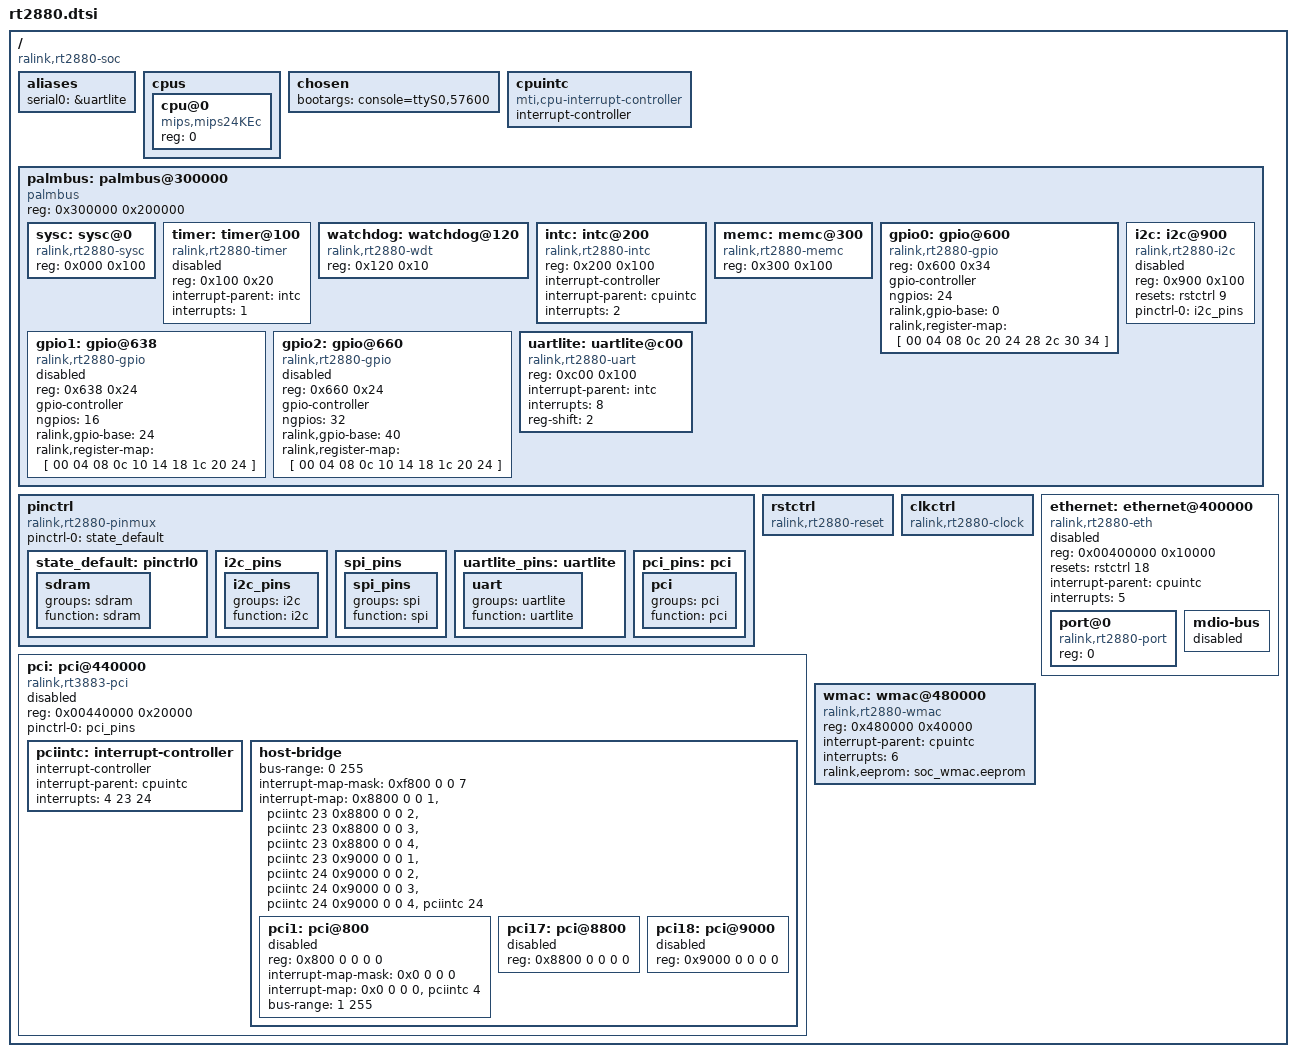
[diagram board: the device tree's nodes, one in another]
/dts-v1/;

/ {
	#address-cells = <1>;
	#size-cells = <1>;
	compatible = "ralink,rt2880-soc";

	aliases {
		serial0 = &uartlite;
	};

	cpus {
		#address-cells = <1>;
		#size-cells = <0>;

		cpu@0 {
			compatible = "mips,mips24KEc";
			reg = <0>;
		};
	};

	chosen {
		bootargs = "console=ttyS0,57600";
	};

	cpuintc: cpuintc {
		#address-cells = <0>;
		#interrupt-cells = <1>;
		interrupt-controller;
		compatible = "mti,cpu-interrupt-controller";
	};

	palmbus: palmbus@300000 {
		compatible = "palmbus";
		reg = <0x300000 0x200000>;
		ranges = <0x0 0x300000 0x1FFFFF>;

		#address-cells = <1>;
		#size-cells = <1>;

		sysc: sysc@0 {
			compatible = "ralink,rt2880-sysc";
			reg = <0x000 0x100>;
		};

		timer: timer@100 {
			compatible = "ralink,rt2880-timer";
			reg = <0x100 0x20>;

			interrupt-parent = <&intc>;
			interrupts = <1>;

			status = "disabled";
		};

		watchdog: watchdog@120 {
			compatible = "ralink,rt2880-wdt";
			reg = <0x120 0x10>;
		};

		intc: intc@200 {
			compatible = "ralink,rt2880-intc";
			reg = <0x200 0x100>;

			interrupt-controller;
			#interrupt-cells = <1>;

			interrupt-parent = <&cpuintc>;
			interrupts = <2>;
		};

		memc: memc@300 {
			compatible = "ralink,rt2880-memc";
			reg = <0x300 0x100>;
		};

		gpio0: gpio@600 {
			compatible = "ralink,rt2880-gpio";
			reg = <0x600 0x34>;

			gpio-controller;
			#gpio-cells = <2>;

			ngpios = <24>;
			ralink,gpio-base = <0>;
			ralink,register-map = [ 00 04 08 0c
						20 24 28 2c
						30 34 ];
		};

		gpio1: gpio@638 {
			compatible = "ralink,rt2880-gpio";
			reg = <0x638 0x24>;

			gpio-controller;
			#gpio-cells = <2>;

			ngpios = <16>;
			ralink,gpio-base = <24>;
			ralink,register-map = [ 00 04 08 0c
						10 14 18 1c
						20 24 ];

			status = "disabled";
		};

		gpio2: gpio@660 {
			compatible = "ralink,rt2880-gpio";
			reg = <0x660 0x24>;

			gpio-controller;
			#gpio-cells = <2>;

			ngpios = <32>;
			ralink,gpio-base = <40>;
			ralink,register-map = [ 00 04 08 0c
						10 14 18 1c
						20 24 ];

			status = "disabled";
		};

		i2c: i2c@900 {
			compatible = "ralink,rt2880-i2c";
			reg = <0x900 0x100>;

			resets = <&rstctrl 9>;
			reset-names = "i2c";

			#address-cells = <1>;
			#size-cells = <0>;

			status = "disabled";

			pinctrl-names = "default";
			pinctrl-0 = <&i2c_pins>;
		};

		uartlite: uartlite@c00 {
			compatible = "ralink,rt2880-uart", "ns16550a";
			reg = <0xc00 0x100>;

			interrupt-parent = <&intc>;
			interrupts = <8>;

			reg-shift = <2>;
		};
	};

	pinctrl: pinctrl {
		compatible = "ralink,rt2880-pinmux";

		pinctrl-names = "default";
		pinctrl-0 = <&state_default>;

		state_default: pinctrl0 {
			sdram {
				groups = "sdram";
				function = "sdram";
			};
		};

		i2c_pins: i2c_pins {
			i2c_pins {
				groups = "i2c";
				function = "i2c";
			};
		};

		spi_pins: spi_pins {
			spi_pins {
				groups = "spi";
				function = "spi";
			};
		};

		uartlite_pins: uartlite {
			uart {
				groups = "uartlite";
				function = "uartlite";
			};
		};

		pci_pins: pci {
			pci {
				groups = "pci";
				function = "pci";
			};
		};

	};

	rstctrl: rstctrl {
		compatible = "ralink,rt2880-reset";
		#reset-cells = <1>;
	};

	clkctrl: clkctrl {
		compatible = "ralink,rt2880-clock";
		#clock-cells = <1>;
	};

	pci: pci@440000 {
		compatible = "ralink,rt3883-pci";
		reg = <0x00440000 0x20000>;
		#address-cells = <1>;
		#size-cells = <1>;
		ranges; /* direct mapping */

		pinctrl-names = "default";
		pinctrl-0 = <&pci_pins>;

		status = "disabled";

		pciintc: interrupt-controller {
			interrupt-controller;
			#address-cells = <0>;
			#interrupt-cells = <1>;

			interrupt-parent = <&cpuintc>;
			interrupts = <4 23 24>;
		};

		host-bridge {
			#address-cells = <3>;
			#size-cells = <2>;
			#interrupt-cells = <1>;

			device_type = "pci";

			bus-range = <0 255>;
			ranges = <0x02000000 0 0 0x20000000 0 0x10000000 /* pci memory */
				  0x01000000 0 0 0x00460000 0 0x00010000 /* io space */
			>;

			interrupt-map-mask = <0xf800 0 0 7>;
			interrupt-map = <
				/* IDSEL 17 */
				0x8800 0 0 1 &pciintc 23
				0x8800 0 0 2 &pciintc 23
				0x8800 0 0 3 &pciintc 23
				0x8800 0 0 4 &pciintc 23
				/* IDSEL 18 */
				0x9000 0 0 1 &pciintc 24
				0x9000 0 0 2 &pciintc 24
				0x9000 0 0 3 &pciintc 24
				0x9000 0 0 4 &pciintc 24
			>;

			pci1: pci@800 {
				reg = <0x800 0 0 0 0>;
				device_type = "pci";
				#interrupt-cells = <1>;
				#address-cells = <3>;
				#size-cells = <2>;

				status = "disabled";

				interrupt-map-mask = <0x0 0 0 0>;
				interrupt-map = <0x0 0 0 0 &pciintc 4>;

				bus-range = <1 255>;
				ranges;
			};

			pci17: pci@8800 {
				reg = <0x8800 0 0 0 0>;
				device_type = "pci";
				#interrupt-cells = <1>;
				#address-cells = <3>;
				#size-cells = <2>;

				status = "disabled";
			};

			pci18: pci@9000 {
				reg = <0x9000 0 0 0 0>;
				device_type = "pci";
				#interrupt-cells = <1>;
				#address-cells = <3>;
				#size-cells = <2>;

				status = "disabled";
			};
		};
	};

	ethernet: ethernet@400000 {
		compatible = "ralink,rt2880-eth";
		reg = <0x00400000 0x10000>;

		#address-cells = <1>;
		#size-cells = <0>;

		resets = <&rstctrl 18>;
		reset-names = "fe";

		interrupt-parent = <&cpuintc>;
		interrupts = <5>;

		status = "disabled";

		port@0 {
			compatible = "ralink,rt2880-port", "mediatek,eth-port";
			reg = <0>;
		};

		mdio-bus {
			#address-cells = <1>;
			#size-cells = <0>;

			status = "disabled";
		};
	};

	wmac: wmac@480000 {
		compatible = "ralink,rt2880-wmac";
		reg = <0x480000 0x40000>;

		interrupt-parent = <&cpuintc>;
		interrupts = <6>;

		ralink,eeprom = "soc_wmac.eeprom";
	};
};
